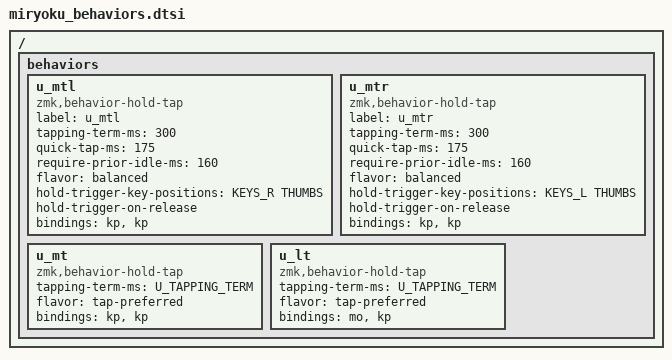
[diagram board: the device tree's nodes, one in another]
// Copyright 2022 Manna Harbour
// https://github.com/manna-harbour/miryoku

/*                                      42 KEY MATRIX / LAYOUT MAPPING

  ╭────────────────────────┬────────────────────────╮ ╭─────────────────────────┬─────────────────────────╮
  │  0   1   2   3   4   5 │  6   7   8   9  10  11 │ │ LT5 LT4 LT3 LT2 LT1 LT0 │ RT0 RT1 RT2 RT3 RT4 RT5 │
  │ 12  13  14  15  16  17 │ 18  19  20  21  22  23 │ │ LM5 LM4 LM3 LM2 LM1 LM0 │ RM0 RM1 RM2 RM3 RM4 RM5 │
  │ 24  25  26  27  28  29 │ 30  31  32  33  34  35 │ │ LB5 LB4 LB3 LB2 LB1 LB0 │ RB0 RB1 RB2 RB3 RB4 RB5 │
  ╰───────────╮ 36  37  38 │ 39  40  41 ╭───────────╯ ╰───────────╮ LH2 LH1 LH0 │ RH0 RH1 RH2 ╭───────────╯
              ╰────────────┴────────────╯                         ╰─────────────┴─────────────╯             */

#define KEYS_L 0 1 2 3 4 5 12 13 14 15 16 17 24 25 26 27 28 29
#define KEYS_R 6 7 8 9 10 11 18 19 20 21 22 23 30 31 32 33 34 35
#define THUMBS 36 37 38 39 40 41

/ {
  behaviors {
    u_mtl: u_mtl {
      compatible = "zmk,behavior-hold-tap";
      label = "u_mtl";
      #binding-cells = <2>;
      tapping-term-ms = <300>;
      quick-tap-ms = <175>;
      require-prior-idle-ms = <160>;
      flavor = "balanced";
      hold-trigger-key-positions = <KEYS_R THUMBS>;
      hold-trigger-on-release;             // delay positional check until key-release
      bindings = <&kp>, <&kp>;
    };
    u_mtr: u_mtr {
      compatible = "zmk,behavior-hold-tap";
      label = "u_mtr";
      #binding-cells = <2>;
      tapping-term-ms = <300>;
      quick-tap-ms = <175>;
      require-prior-idle-ms = <160>;
      flavor = "balanced";
      hold-trigger-key-positions = <KEYS_L THUMBS>;
      hold-trigger-on-release;             // delay positional check until key-release
      bindings = <&kp>, <&kp>;
    };
    u_mt: u_mt {
      compatible = "zmk,behavior-hold-tap";
      #binding-cells = <2>;
      tapping-term-ms = <U_TAPPING_TERM>;
      flavor = "tap-preferred";
      bindings = <&kp>, <&kp>;
    };
    u_lt: u_lt {
      compatible = "zmk,behavior-hold-tap";
      #binding-cells = <2>;
      tapping-term-ms = <U_TAPPING_TERM>;
      flavor = "tap-preferred";
      bindings = <&mo>, <&kp>;
    };
  };
};
